# f28p65x_adc_safecheck_intevt_regs register map
Vendor: Texas Instruments
Peripheral module from a debugger description file (folder C2000).
Address unit: 16 bits
Registers are 32-bit, read-write, no defined reset value unless marked. A register's access mark holds for its fields unless they carry their own. Offsets are as the file gives them; lines under a group give offsets from that group; [hi:lo] are bit positions; {n}, {i} and the like mark numbered series; 'fields as' and 'values as' point back to an identical list; <NAME> marks a mode.

## ADC_SAFECHECK_INTEVT_REGS — ADC SAFECHECK INTEVT Registers
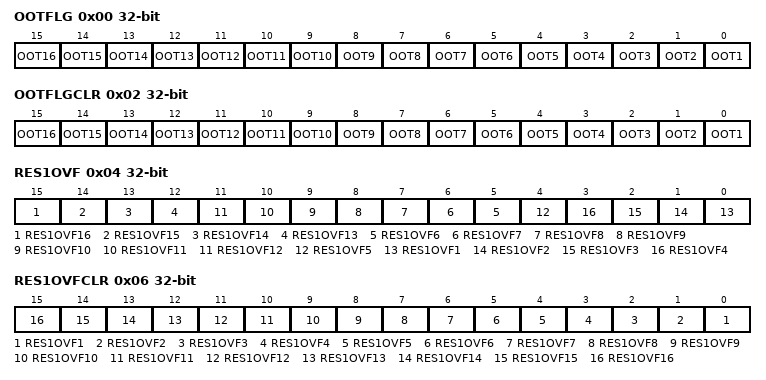
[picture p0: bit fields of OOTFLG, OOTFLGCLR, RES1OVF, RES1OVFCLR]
0x00 OOTFLG ro — Checker Out-of-Tolerance Flag Register
  [n-1] OOT{n} (n=1..16) — Checker {n} Out-of-Tolerance Flag
0x02 OOTFLGCLR — Checker Out-of-Tolerance Flag Clear Register
  [n-1] OOT{n} (n=1..16) — Checker {n} OOT Flag Clear
0x04 RES1OVF ro — Checker Overflow Result 1 Flag Register
  [15] RES1OVF16 — Checker 16 Result 1 Overflow Flag
  [14] RES1OVF15 — Checker 15 Result 1 Overflow Flag
  [13] RES1OVF14 — Checker 14 Result 1 Overflow Flag
  [12] RES1OVF13 — Checker 13 Result 5 Overflow Flag
  [n-1] RES1OVF{n} (n=6..12) — Checker {n} Result 1 Overflow Flag
  [4] RES1OVF5 — Checker 5 Result 5 Overflow Flag
  [n-1] RES1OVF{n} (n=1..4) — Checker {n} Result 1 Overflow Flag
0x06 RES1OVFCLR — Checker Overflow Result 1 Flag Clear Register
  [n-1] RES1OVF{n} (n=1..16) — Checker {n} Result 1 OVF Flag Clear
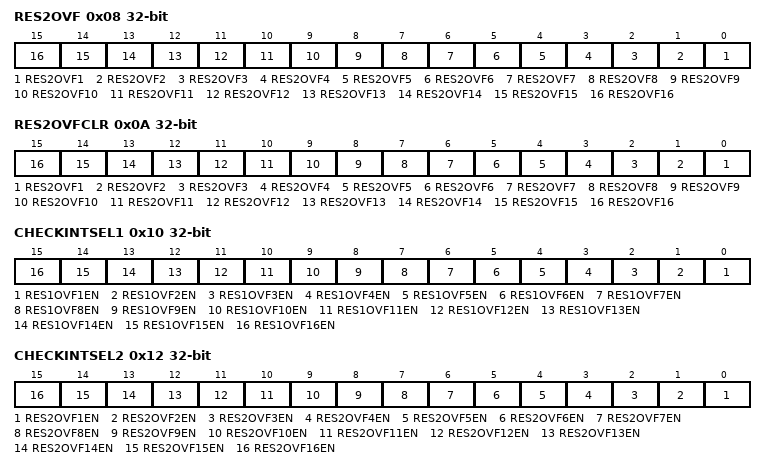
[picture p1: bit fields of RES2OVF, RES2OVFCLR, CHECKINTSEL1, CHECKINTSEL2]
0x08 RES2OVF ro — Checker Overflow Result 2 Flag Register
  [n-1] RES2OVF{n} (n=1..16) — Checker {n} Result 2 Overflow Flag
0x0A RES2OVFCLR — Checker Overflow Result 2 Flag Clear Register
  [n-1] RES2OVF{n} (n=1..16) — Checker {n} Result 2 OVF Flag Clear
0x0C CHECKINTFLG 16-bit ro — Checker Interrupt Flag Register
  [0] CHECKINT — ADC Safety Checker Subsystem Interrupt Flag
0x0E CHECKINTFLGCLR 16-bit — Checker Interrupt Flag Clear Register
  [0] CHECKINTCLR — ADC Safety Checker Subsystem Interrupt Flag Clear
0x10 CHECKINTSEL1 — Checker Interrupt Source Select Register 1
  [n-1] RES1OVF{n}EN (n=1..16) — Overflow Enable from Checker {n} Result 1
0x12 CHECKINTSEL2 — Checker Interrupt Source Select Register 2
  [n-1] RES2OVF{n}EN (n=1..16) — Overflow Enable from Checker {n} Result 2
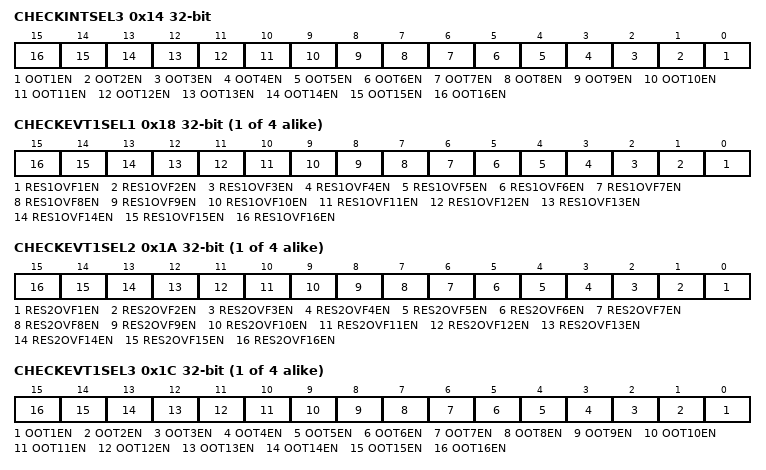
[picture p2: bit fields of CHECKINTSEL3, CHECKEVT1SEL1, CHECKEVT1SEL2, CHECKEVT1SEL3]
0x14 CHECKINTSEL3 — Checker Interrupt Source Select Register 3
  [n-1] OOT{n}EN (n=1..16) — Out-of-Tolerance Enable from Checker {n}
{0x10+8i} CHECKEVT{i}SEL1 (i=1..4) — Checker X-Bar EVT{i} Source Select Register 1
  fields as CHECKINTSEL1
{0x12+8i} CHECKEVT{i}SEL2 (i=1..4) — Checker X-Bar EVT{i} Source Select Register 2
  fields as CHECKINTSEL2
{0x14+8i} CHECKEVT{i}SEL3 (i=1..4) — Checker X-Bar EVT{i} Source Select Register 3
  [n-1] OOT{n}EN (n=1..16) — Out-of-Tolerance Enable from Checker {n}
